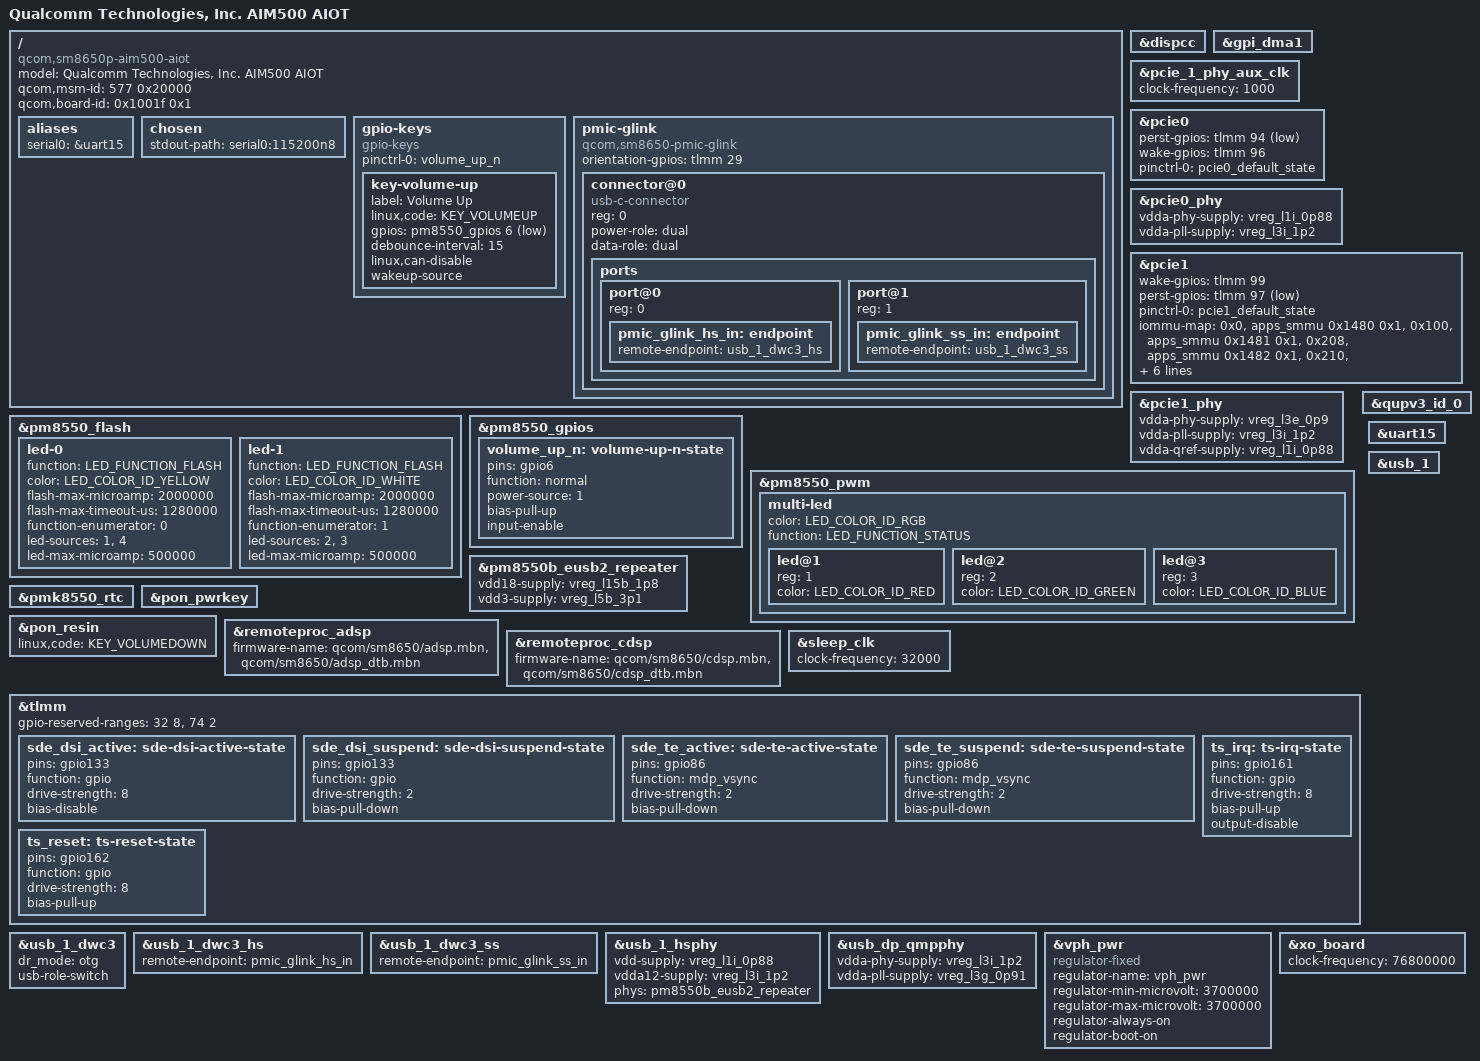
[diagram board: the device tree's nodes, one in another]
// SPDX-License-Identifier: BSD-3-Clause
/*
 * Copyright (c) 2024, Qualcomm Innovation Center, Inc. All rights reserved.
 */

/dts-v1/;

#include <dt-bindings/leds/common.h>
#include "sm8650p-aim500.dtsi"
#include "pm8010.dtsi"
#include "pmr735d_a.dtsi"

/ {
	model = "Qualcomm Technologies, Inc. AIM500 AIOT";
	compatible = "qcom,sm8650p-aim500-aiot", "qcom,sm8650p-aim500", "qcom,sm8650p",
		     "qcom,sm8650";

	qcom,msm-id = <577 0x20000>;
	qcom,board-id = <0x1001f 0x1>;

	aliases {
		serial0 = &uart15;
	};

	chosen {
		stdout-path = "serial0:115200n8";
	};

	gpio-keys {
		compatible = "gpio-keys";

		pinctrl-0 = <&volume_up_n>;
		pinctrl-names = "default";

		key-volume-up {
			label = "Volume Up";
			linux,code = <KEY_VOLUMEUP>;
			gpios = <&pm8550_gpios 6 GPIO_ACTIVE_LOW>;
			debounce-interval = <15>;
			linux,can-disable;
			wakeup-source;
		};
	};

	pmic-glink {
		compatible = "qcom,sm8650-pmic-glink",
			     "qcom,sm8550-pmic-glink",
			     "qcom,pmic-glink";
		#address-cells = <1>;
		#size-cells = <0>;
		orientation-gpios = <&tlmm 29 GPIO_ACTIVE_HIGH>;

		connector@0 {
			compatible = "usb-c-connector";
			reg = <0>;

			power-role = "dual";
			data-role = "dual";

			ports {
				#address-cells = <1>;
				#size-cells = <0>;

				port@0 {
					reg = <0>;

					pmic_glink_hs_in: endpoint {
						remote-endpoint = <&usb_1_dwc3_hs>;
					};
				};

				port@1 {
					reg = <1>;

					pmic_glink_ss_in: endpoint {
						remote-endpoint = <&usb_1_dwc3_ss>;
					};
				};
			};
		};
	};
};

&dispcc {
	status = "okay";
};

&gpi_dma1 {
	status = "okay";
};

&pcie_1_phy_aux_clk {
	clock-frequency = <1000>;
};

&pcie0 {
	perst-gpios = <&tlmm 94 GPIO_ACTIVE_LOW>;
	wake-gpios = <&tlmm 96 GPIO_ACTIVE_HIGH>;

	pinctrl-0 = <&pcie0_default_state>;
	pinctrl-names = "default";

	status = "okay";
};

&pcie0_phy {
	vdda-phy-supply = <&vreg_l1i_0p88>;
	vdda-pll-supply = <&vreg_l3i_1p2>;

	status = "okay";
};

&pcie1 {
	wake-gpios = <&tlmm 99 GPIO_ACTIVE_HIGH>;
	perst-gpios = <&tlmm 97 GPIO_ACTIVE_LOW>;

	pinctrl-0 = <&pcie1_default_state>;
	pinctrl-names = "default";

	iommu-map = <0x0 &apps_smmu 0x1480 0x1>,
		<0x100 &apps_smmu 0x1481 0x1>,
		<0x208 &apps_smmu 0x1482 0x1>,
		<0x210 &apps_smmu 0x1483 0x1>,
		<0x218 &apps_smmu 0x1484 0x1>,
		<0x300 &apps_smmu 0x1487 0x1>,
		<0x400 &apps_smmu 0x1488 0x1>,
		<0x500 &apps_smmu 0x148c 0x1>,
		<0x501 &apps_smmu 0x148e 0x1>;

	status = "okay";
};

&pcie1_phy {
	vdda-phy-supply = <&vreg_l3e_0p9>;
	vdda-pll-supply = <&vreg_l3i_1p2>;
	vdda-qref-supply = <&vreg_l1i_0p88>;

	status = "okay";
};

&pm8550_flash {
	status = "okay";

	led-0 {
		function = LED_FUNCTION_FLASH;
		color = <LED_COLOR_ID_YELLOW>;
		flash-max-microamp = <2000000>;
		flash-max-timeout-us = <1280000>;
		function-enumerator = <0>;
		led-sources = <1>, <4>;
		led-max-microamp = <500000>;
	};

	led-1 {
		function = LED_FUNCTION_FLASH;
		color = <LED_COLOR_ID_WHITE>;
		flash-max-microamp = <2000000>;
		flash-max-timeout-us = <1280000>;
		function-enumerator = <1>;
		led-sources = <2>, <3>;
		led-max-microamp = <500000>;
	};
};

&pm8550_gpios {
	volume_up_n: volume-up-n-state {
		pins = "gpio6";
		function = "normal";
		power-source = <1>;
		bias-pull-up;
		input-enable;
	};
};

&pm8550_pwm {
	status = "okay";

	multi-led {
		color = <LED_COLOR_ID_RGB>;
		function = LED_FUNCTION_STATUS;

		#address-cells = <1>;
		#size-cells = <0>;

		led@1 {
			reg = <1>;
			color = <LED_COLOR_ID_RED>;
		};

		led@2 {
			reg = <2>;
			color = <LED_COLOR_ID_GREEN>;
		};

		led@3 {
			reg = <3>;
			color = <LED_COLOR_ID_BLUE>;
		};
	};
};

&pm8550b_eusb2_repeater {
	vdd18-supply = <&vreg_l15b_1p8>;
	vdd3-supply = <&vreg_l5b_3p1>;
};

&pmk8550_rtc {
	status = "okay";
};

&pon_pwrkey {
	status = "okay";
};

&pon_resin {
	linux,code = <KEY_VOLUMEDOWN>;

	status = "okay";
};

&qupv3_id_0 {
	status = "okay";
};

&remoteproc_adsp {
	firmware-name = "qcom/sm8650/adsp.mbn",
			"qcom/sm8650/adsp_dtb.mbn";

	status = "okay";
};

&remoteproc_cdsp {
	firmware-name = "qcom/sm8650/cdsp.mbn",
			"qcom/sm8650/cdsp_dtb.mbn";

	status = "okay";
};

&sleep_clk {
	clock-frequency = <32000>;
};

&tlmm {
	gpio-reserved-ranges = <32 8>, <74 2>;

	sde_dsi_active: sde-dsi-active-state {
		pins = "gpio133";
		function = "gpio";
		drive-strength = <8>;
		bias-disable;
	};

	sde_dsi_suspend: sde-dsi-suspend-state {
		pins = "gpio133";
		function = "gpio";
		drive-strength = <2>;
		bias-pull-down;
	};

	sde_te_active: sde-te-active-state {
		pins = "gpio86";
		function = "mdp_vsync";
		drive-strength = <2>;
		bias-pull-down;
	};

	sde_te_suspend: sde-te-suspend-state {
		pins = "gpio86";
		function = "mdp_vsync";
		drive-strength = <2>;
		bias-pull-down;
	};

	ts_irq: ts-irq-state {
		pins = "gpio161";
		function = "gpio";
		drive-strength = <8>;
		bias-pull-up;
		output-disable;
	};

	ts_reset: ts-reset-state {
		pins = "gpio162";
		function = "gpio";
		drive-strength = <8>;
		bias-pull-up;
	};
};

&uart15 {
	status = "okay";
};

/*
 * DPAUX -> WCD9395 -> USB_SBU -> USB-C
 * eUSB2 DP/DM -> PM85550HS -> eUSB2 DP/DM -> WCD9395 -> USB-C
 * USB SS -> NB7VPQ904MMUTWG -> USB-C
 */

&usb_1 {
	status = "okay";
};

&usb_1_dwc3 {
	dr_mode = "otg";
	usb-role-switch;
};

&usb_1_dwc3_hs {
	remote-endpoint = <&pmic_glink_hs_in>;
};

&usb_1_dwc3_ss {
	remote-endpoint = <&pmic_glink_ss_in>;
};

&usb_1_hsphy {
	vdd-supply = <&vreg_l1i_0p88>;
	vdda12-supply = <&vreg_l3i_1p2>;

	phys = <&pm8550b_eusb2_repeater>;

	status = "okay";
};

&usb_dp_qmpphy {
	vdda-phy-supply = <&vreg_l3i_1p2>;
	vdda-pll-supply = <&vreg_l3g_0p91>;

	status = "okay";
};

&vph_pwr {
	compatible = "regulator-fixed";
	regulator-name = "vph_pwr";
	regulator-min-microvolt = <3700000>;
	regulator-max-microvolt = <3700000>;

	regulator-always-on;
	regulator-boot-on;
};

&xo_board {
	clock-frequency = <76800000>;
};
